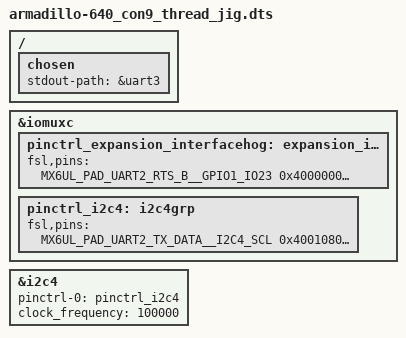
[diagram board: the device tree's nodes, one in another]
/*
 * Copyright (C) 2019 Atmark Techno, Inc. All Rights Reserved.
 *
 * SPDX-License-Identifier: (GPL-2.0 OR MIT)
 */

/dts-v1/;

#define ARMADILLO640_AT_DTWEB
#include "armadillo-640.dts"

/ {
	chosen {
		stdout-path = &uart3;
	};
};

&iomuxc {
	pinctrl-names = "default";

	pinctrl_expansion_interfacehog: expansion_interfacehoggrp {
		fsl,pins = <
			MX6UL_PAD_UART2_RTS_B__GPIO1_IO23	0x40000008	/* CON1_6  SWDCLK */
			MX6UL_PAD_UART5_RX_DATA__GPIO1_IO31	0x40010008	/* CON1_8  SWDIO */
			MX6UL_PAD_UART5_TX_DATA__GPIO1_IO30	0x00000008	/* CON1_10 HUB_RESET_B */
			MX6UL_PAD_LCD_DATA20__GPIO3_IO25	0x40000008	/* CON1_19 WLAN_PWREN */
			MX6UL_PAD_LCD_DATA21__GPIO3_IO26	0x00000008	/* CON1_20 BLE_RESET */
			MX6UL_PAD_LCD_DATA22__GPIO3_IO27	0x00000008	/* CON1_21 BLE_PWR_EN */
			MX6UL_PAD_LCD_DATA23__GPIO3_IO28	0x00000008	/* CON1_22 SE_RST_N */

			MX6UL_PAD_UART1_RX_DATA__GPIO1_IO17	0x400010b0	/* CON9_3 JIG_3_3V */
			MX6UL_PAD_UART1_TX_DATA__GPIO1_IO16	0x400010b0	/* CON9_5 JIG_TARGET_ON */

			MX6UL_PAD_CSI_MCLK__GPIO4_IO17     	0x00008		/* USBOTG2_VBUS */
		>;
	};


	pinctrl_i2c4: i2c4grp {
		fsl,pins = <
			MX6UL_PAD_UART2_TX_DATA__I2C4_SCL	0x40010808	/* CON1_3 */
			MX6UL_PAD_UART2_RX_DATA__I2C4_SDA	0x40010808	/* CON1_4 */
		>;
	};
};

&i2c4 {
	pinctrl-names = "default";
	pinctrl-0 = <&pinctrl_i2c4>;
	clock_frequency = <100000>;
	status = "okay";
};
